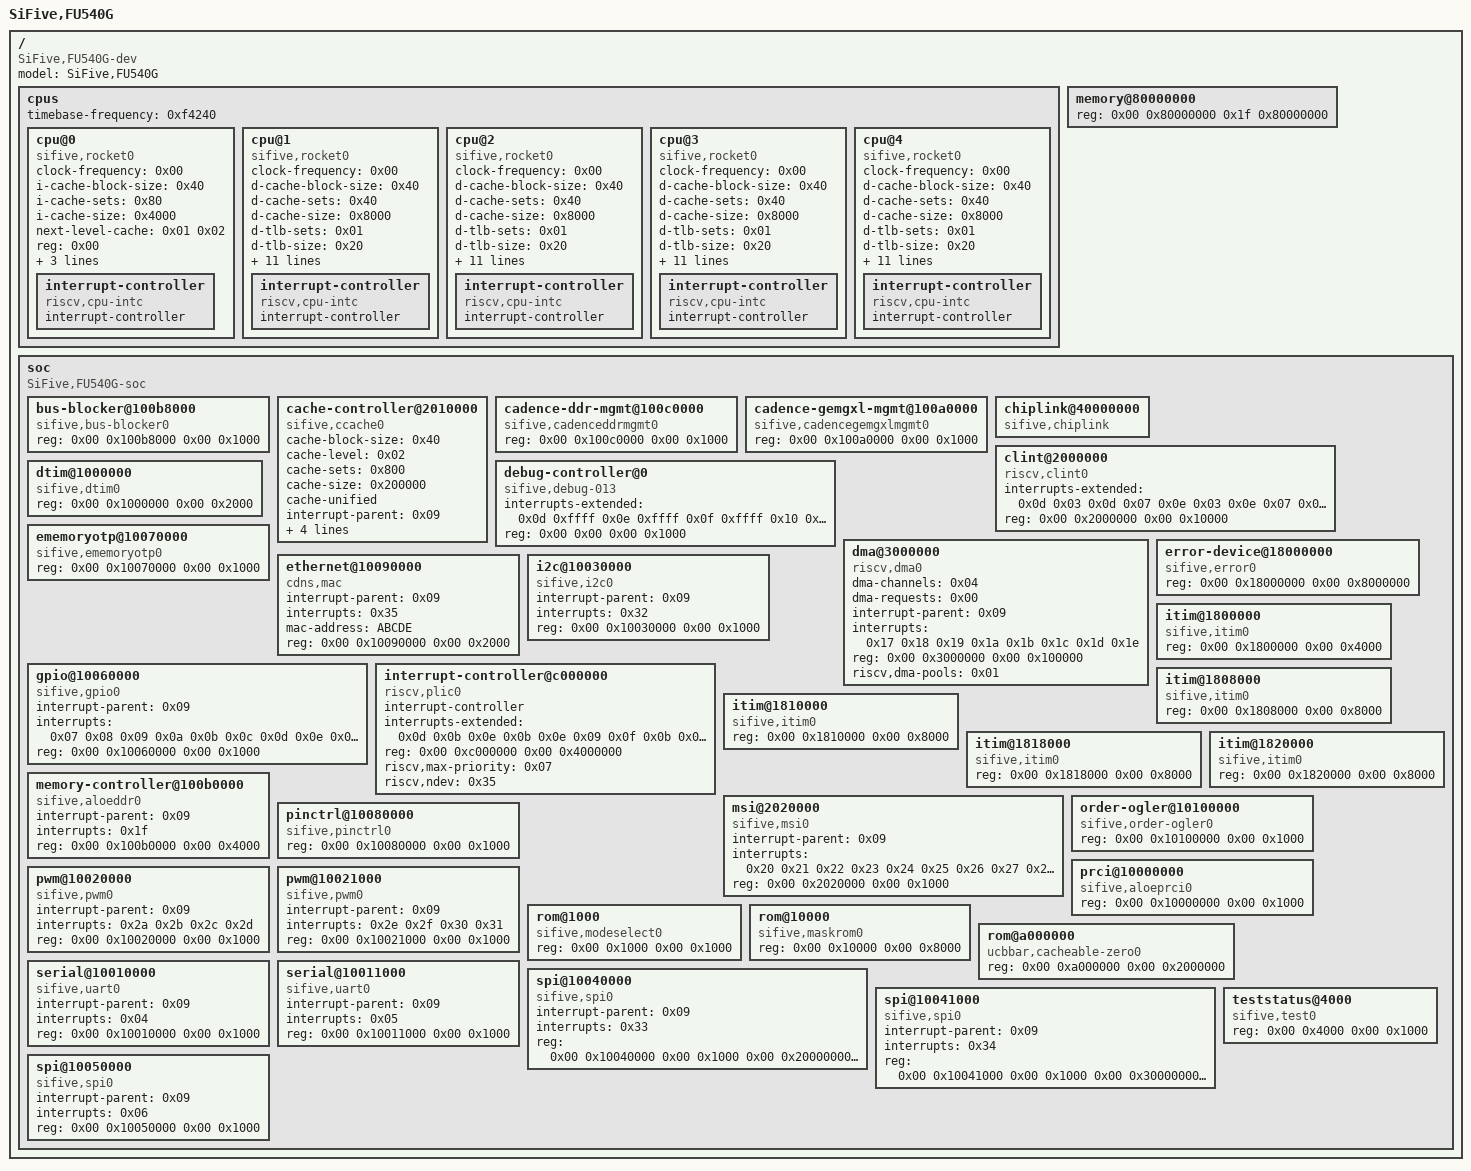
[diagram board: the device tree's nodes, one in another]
/* Copyright (c) 2018 SiFive, Inc */
/* SPDX-License-Identifier: Apache-2.0 */
/* SPDX-License-Identifier: GPL-2.0-or-later */
/* See the file LICENSE for further information */

/* From @SirCmpwn */

/dts-v1/;

/ {
	#address-cells = < 0x02 >;
	#size-cells = < 0x02 >;
	compatible = "SiFive,FU540G-dev\0fu500-dev\0sifive-dev";
	model = "SiFive,FU540G";

	cpus {
		#address-cells = < 0x01 >;
		#size-cells = < 0x00 >;
		timebase-frequency = < 0xf4240 >;

		cpu@0 {
			clock-frequency = < 0x00 >;
			compatible = "sifive,rocket0\0riscv";
			device_type = "cpu";
			i-cache-block-size = < 0x40 >;
			i-cache-sets = < 0x80 >;
			i-cache-size = < 0x4000 >;
			next-level-cache = < 0x01 0x02 >;
			reg = < 0x00 >;
			riscv,isa = "rv64imac";
			sifive,dtim = < 0x03 >;
			sifive,itim = < 0x04 >;
			status = "okay";

			interrupt-controller {
				#interrupt-cells = < 0x01 >;
				compatible = "riscv,cpu-intc";
				interrupt-controller;
				linux,phandle = < 0x0d >;
				phandle = < 0x0d >;
			};
		};

		cpu@1 {
			clock-frequency = < 0x00 >;
			compatible = "sifive,rocket0\0riscv";
			d-cache-block-size = < 0x40 >;
			d-cache-sets = < 0x40 >;
			d-cache-size = < 0x8000 >;
			d-tlb-sets = < 0x01 >;
			d-tlb-size = < 0x20 >;
			device_type = "cpu";
			i-cache-block-size = < 0x40 >;
			i-cache-sets = < 0x40 >;
			i-cache-size = < 0x8000 >;
			i-tlb-sets = < 0x01 >;
			i-tlb-size = < 0x20 >;
			mmu-type = "riscv,sv39";
			next-level-cache = < 0x01 0x02 >;
			reg = < 0x01 >;
			riscv,isa = "rv64imafdc";
			sifive,itim = < 0x05 >;
			status = "okay";
			tlb-split;

			interrupt-controller {
				#interrupt-cells = < 0x01 >;
				compatible = "riscv,cpu-intc";
				interrupt-controller;
				linux,phandle = < 0x0e >;
				phandle = < 0x0e >;
			};
		};

		cpu@2 {
			clock-frequency = < 0x00 >;
			compatible = "sifive,rocket0\0riscv";
			d-cache-block-size = < 0x40 >;
			d-cache-sets = < 0x40 >;
			d-cache-size = < 0x8000 >;
			d-tlb-sets = < 0x01 >;
			d-tlb-size = < 0x20 >;
			device_type = "cpu";
			i-cache-block-size = < 0x40 >;
			i-cache-sets = < 0x40 >;
			i-cache-size = < 0x8000 >;
			i-tlb-sets = < 0x01 >;
			i-tlb-size = < 0x20 >;
			mmu-type = "riscv,sv39";
			next-level-cache = < 0x01 0x02 >;
			reg = < 0x02 >;
			riscv,isa = "rv64imafdc";
			sifive,itim = < 0x06 >;
			status = "okay";
			tlb-split;

			interrupt-controller {
				#interrupt-cells = < 0x01 >;
				compatible = "riscv,cpu-intc";
				interrupt-controller;
				linux,phandle = < 0x0f >;
				phandle = < 0x0f >;
			};
		};

		cpu@3 {
			clock-frequency = < 0x00 >;
			compatible = "sifive,rocket0\0riscv";
			d-cache-block-size = < 0x40 >;
			d-cache-sets = < 0x40 >;
			d-cache-size = < 0x8000 >;
			d-tlb-sets = < 0x01 >;
			d-tlb-size = < 0x20 >;
			device_type = "cpu";
			i-cache-block-size = < 0x40 >;
			i-cache-sets = < 0x40 >;
			i-cache-size = < 0x8000 >;
			i-tlb-sets = < 0x01 >;
			i-tlb-size = < 0x20 >;
			mmu-type = "riscv,sv39";
			next-level-cache = < 0x01 0x02 >;
			reg = < 0x03 >;
			riscv,isa = "rv64imafdc";
			sifive,itim = < 0x07 >;
			status = "okay";
			tlb-split;

			interrupt-controller {
				#interrupt-cells = < 0x01 >;
				compatible = "riscv,cpu-intc";
				interrupt-controller;
				linux,phandle = < 0x10 >;
				phandle = < 0x10 >;
			};
		};

		cpu@4 {
			clock-frequency = < 0x00 >;
			compatible = "sifive,rocket0\0riscv";
			d-cache-block-size = < 0x40 >;
			d-cache-sets = < 0x40 >;
			d-cache-size = < 0x8000 >;
			d-tlb-sets = < 0x01 >;
			d-tlb-size = < 0x20 >;
			device_type = "cpu";
			i-cache-block-size = < 0x40 >;
			i-cache-sets = < 0x40 >;
			i-cache-size = < 0x8000 >;
			i-tlb-sets = < 0x01 >;
			i-tlb-size = < 0x20 >;
			mmu-type = "riscv,sv39";
			next-level-cache = < 0x01 0x02 >;
			reg = < 0x04 >;
			riscv,isa = "rv64imafdc";
			sifive,itim = < 0x08 >;
			status = "okay";
			tlb-split;

			interrupt-controller {
				#interrupt-cells = < 0x01 >;
				compatible = "riscv,cpu-intc";
				interrupt-controller;
				linux,phandle = < 0x11 >;
				phandle = < 0x11 >;
			};
		};
	};

	memory@80000000 {
		device_type = "memory";
		reg = < 0x00 0x80000000 0x1f 0x80000000 >;
		linux,phandle = < 0x0c >;
		phandle = < 0x0c >;
	};

	soc {
		#address-cells = < 0x02 >;
		#size-cells = < 0x02 >;
		compatible = "SiFive,FU540G-soc\0fu500-soc\0sifive-soc\0simple-bus";
		ranges;

		bus-blocker@100b8000 {
			compatible = "sifive,bus-blocker0";
			reg = < 0x00 0x100b8000 0x00 0x1000 >;
			reg-names = "control";
		};

		cache-controller@2010000 {
			cache-block-size = < 0x40 >;
			cache-level = < 0x02 >;
			cache-sets = < 0x800 >;
			cache-size = < 0x200000 >;
			cache-unified;
			compatible = "sifive,ccache0\0cache";
			interrupt-parent = < 0x09 >;
			interrupts = < 0x01 0x02 0x03 >;
			next-level-cache = < 0x0a 0x0b 0x0c >;
			reg = < 0x00 0x2010000 0x00 0x1000 0x00 0x8000000 0x00 0x2000000 >;
			reg-names = "control\0sideband";
			linux,phandle = < 0x02 >;
			phandle = < 0x02 >;
		};

		cadence-ddr-mgmt@100c0000 {
			compatible = "sifive,cadenceddrmgmt0";
			reg = < 0x00 0x100c0000 0x00 0x1000 >;
			reg-names = "control";
		};

		cadence-gemgxl-mgmt@100a0000 {
			compatible = "sifive,cadencegemgxlmgmt0";
			reg = < 0x00 0x100a0000 0x00 0x1000 >;
			reg-names = "control";
		};

		chiplink@40000000 {
			#address-cells = < 0x02 >;
			#size-cells = < 0x02 >;
			compatible = "sifive,chiplink\0simple-bus";
			ranges = < 0x00 0x60000000 0x00 0x60000000 0x00 0x20000000 0x30 0x00 0x30 0x00 0x10 0x00 0x00 0x40000000 0x00 0x40000000 0x00 0x20000000 0x20 0x00 0x20 0x00 0x10 0x00 >;
			linux,phandle = < 0x0b >;
			phandle = < 0x0b >;
		};

		clint@2000000 {
			compatible = "riscv,clint0";
			interrupts-extended = < 0x0d 0x03 0x0d 0x07 0x0e 0x03 0x0e 0x07 0x0f 0x03 0x0f 0x07 0x10 0x03 0x10 0x07 0x11 0x03 0x11 0x07 >;
			reg = < 0x00 0x2000000 0x00 0x10000 >;
			reg-names = "control";
		};

		debug-controller@0 {
			compatible = "sifive,debug-013\0riscv,debug-013";
			interrupts-extended = < 0x0d 0xffff 0x0e 0xffff 0x0f 0xffff 0x10 0xffff 0x11 0xffff >;
			reg = < 0x00 0x00 0x00 0x1000 >;
			reg-names = "control";
		};

		dma@3000000 {
			#dma-cells = < 0x01 >;
			compatible = "riscv,dma0";
			dma-channels = < 0x04 >;
			dma-requests = < 0x00 >;
			interrupt-parent = < 0x09 >;
			interrupts = < 0x17 0x18 0x19 0x1a 0x1b 0x1c 0x1d 0x1e >;
			reg = < 0x00 0x3000000 0x00 0x100000 >;
			reg-names = "control";
			riscv,dma-pools = < 0x01 >;
		};

		dtim@1000000 {
			compatible = "sifive,dtim0";
			reg = < 0x00 0x1000000 0x00 0x2000 >;
			reg-names = "mem";
			linux,phandle = < 0x03 >;
			phandle = < 0x03 >;
		};

		ememoryotp@10070000 {
			compatible = "sifive,ememoryotp0";
			reg = < 0x00 0x10070000 0x00 0x1000 >;
			reg-names = "control";
		};

		error-device@18000000 {
			compatible = "sifive,error0";
			reg = < 0x00 0x18000000 0x00 0x8000000 >;
			reg-names = "mem";
			linux,phandle = < 0x01 >;
			phandle = < 0x01 >;
		};

		ethernet@10090000 {
			compatible = "cdns,mac";
			interrupt-parent = < 0x09 >;
			interrupts = < 0x35 >;
			mac-address = "ABCDE";
			reg = < 0x00 0x10090000 0x00 0x2000 >;
			reg-names = "control";
		};

		gpio@10060000 {
			compatible = "sifive,gpio0";
			interrupt-parent = < 0x09 >;
			interrupts = < 0x07 0x08 0x09 0x0a 0x0b 0x0c 0x0d 0x0e 0x0f 0x10 0x11 0x12 0x13 0x14 0x15 0x16 >;
			reg = < 0x00 0x10060000 0x00 0x1000 >;
			reg-names = "control";
		};

		i2c@10030000 {
			compatible = "sifive,i2c0";
			interrupt-parent = < 0x09 >;
			interrupts = < 0x32 >;
			reg = < 0x00 0x10030000 0x00 0x1000 >;
			reg-names = "control";
		};

		interrupt-controller@c000000 {
			#interrupt-cells = < 0x01 >;
			compatible = "riscv,plic0";
			interrupt-controller;
			interrupts-extended = < 0x0d 0x0b 0x0e 0x0b 0x0e 0x09 0x0f 0x0b 0x0f 0x09 0x10 0x0b 0x10 0x09 0x11 0x0b 0x11 0x09 >;
			reg = < 0x00 0xc000000 0x00 0x4000000 >;
			reg-names = "control";
			riscv,max-priority = < 0x07 >;
			riscv,ndev = < 0x35 >;
			linux,phandle = < 0x09 >;
			phandle = < 0x09 >;
		};

		itim@1800000 {
			compatible = "sifive,itim0";
			reg = < 0x00 0x1800000 0x00 0x4000 >;
			reg-names = "mem";
			linux,phandle = < 0x04 >;
			phandle = < 0x04 >;
		};

		itim@1808000 {
			compatible = "sifive,itim0";
			reg = < 0x00 0x1808000 0x00 0x8000 >;
			reg-names = "mem";
			linux,phandle = < 0x05 >;
			phandle = < 0x05 >;
		};

		itim@1810000 {
			compatible = "sifive,itim0";
			reg = < 0x00 0x1810000 0x00 0x8000 >;
			reg-names = "mem";
			linux,phandle = < 0x06 >;
			phandle = < 0x06 >;
		};

		itim@1818000 {
			compatible = "sifive,itim0";
			reg = < 0x00 0x1818000 0x00 0x8000 >;
			reg-names = "mem";
			linux,phandle = < 0x07 >;
			phandle = < 0x07 >;
		};

		itim@1820000 {
			compatible = "sifive,itim0";
			reg = < 0x00 0x1820000 0x00 0x8000 >;
			reg-names = "mem";
			linux,phandle = < 0x08 >;
			phandle = < 0x08 >;
		};

		memory-controller@100b0000 {
			compatible = "sifive,aloeddr0";
			interrupt-parent = < 0x09 >;
			interrupts = < 0x1f >;
			reg = < 0x00 0x100b0000 0x00 0x4000 >;
			reg-names = "control";
		};

		msi@2020000 {
			compatible = "sifive,msi0";
			interrupt-parent = < 0x09 >;
			interrupts = < 0x20 0x21 0x22 0x23 0x24 0x25 0x26 0x27 0x28 0x29 >;
			reg = < 0x00 0x2020000 0x00 0x1000 >;
			reg-names = "control";
		};

		order-ogler@10100000 {
			compatible = "sifive,order-ogler0";
			reg = < 0x00 0x10100000 0x00 0x1000 >;
			reg-names = "control";
		};

		pinctrl@10080000 {
			compatible = "sifive,pinctrl0";
			reg = < 0x00 0x10080000 0x00 0x1000 >;
			reg-names = "control";
		};

		prci@10000000 {
			compatible = "sifive,aloeprci0";
			reg = < 0x00 0x10000000 0x00 0x1000 >;
			reg-names = "control";
		};

		pwm@10020000 {
			compatible = "sifive,pwm0";
			interrupt-parent = < 0x09 >;
			interrupts = < 0x2a 0x2b 0x2c 0x2d >;
			reg = < 0x00 0x10020000 0x00 0x1000 >;
			reg-names = "control";
		};

		pwm@10021000 {
			compatible = "sifive,pwm0";
			interrupt-parent = < 0x09 >;
			interrupts = < 0x2e 0x2f 0x30 0x31 >;
			reg = < 0x00 0x10021000 0x00 0x1000 >;
			reg-names = "control";
		};

		rom@1000 {
			compatible = "sifive,modeselect0";
			reg = < 0x00 0x1000 0x00 0x1000 >;
			reg-names = "mem";
		};

		rom@10000 {
			compatible = "sifive,maskrom0";
			reg = < 0x00 0x10000 0x00 0x8000 >;
			reg-names = "mem";
		};

		rom@a000000 {
			compatible = "ucbbar,cacheable-zero0";
			reg = < 0x00 0xa000000 0x00 0x2000000 >;
			reg-names = "mem";
			linux,phandle = < 0x0a >;
			phandle = < 0x0a >;
		};

		serial@10010000 {
			compatible = "sifive,uart0";
			interrupt-parent = < 0x09 >;
			interrupts = < 0x04 >;
			reg = < 0x00 0x10010000 0x00 0x1000 >;
			reg-names = "control";
		};

		serial@10011000 {
			compatible = "sifive,uart0";
			interrupt-parent = < 0x09 >;
			interrupts = < 0x05 >;
			reg = < 0x00 0x10011000 0x00 0x1000 >;
			reg-names = "control";
		};

		spi@10040000 {
			compatible = "sifive,spi0";
			interrupt-parent = < 0x09 >;
			interrupts = < 0x33 >;
			reg = < 0x00 0x10040000 0x00 0x1000 0x00 0x20000000 0x00 0x10000000 >;
			reg-names = "control\0mem";
		};

		spi@10041000 {
			compatible = "sifive,spi0";
			interrupt-parent = < 0x09 >;
			interrupts = < 0x34 >;
			reg = < 0x00 0x10041000 0x00 0x1000 0x00 0x30000000 0x00 0x10000000 >;
			reg-names = "control\0mem";
		};

		spi@10050000 {
			compatible = "sifive,spi0";
			interrupt-parent = < 0x09 >;
			interrupts = < 0x06 >;
			reg = < 0x00 0x10050000 0x00 0x1000 >;
			reg-names = "control";
		};

		teststatus@4000 {
			compatible = "sifive,test0";
			reg = < 0x00 0x4000 0x00 0x1000 >;
			reg-names = "control";
		};
	};
};
